# CTRL_MODULE_CORE register map
Vendor: Texas Instruments
Registers are 32-bit, read-only, reset 0x0 unless marked. A register's access mark holds for its fields unless they carry their own. Offsets are as the file gives them; [hi:lo] are bit positions; {n}, {i} and the like mark numbered series.

## CTRL_MODULE_CORE (part 2 of 2)
0x448 CONTROL_CONF_CLK_SEL2 access per field reset 0x2 — clk view channel 2 Access conditions. Read: unrestricted, Write: unrestricted
  [3:0] MULT rw — Select one of the following signals :
    6=MULT_I6 (hwobs_satadpll_clkout); 1=MULT_I1 (hwobs_abedpll_clkout); 10=MULT_I10 (Reserved); 7=MULT_I7 (hwobs_usbotgssdpll_clkout); 0=MULT_I0 (hwobs_coredpll_clkout); 2=MULT_I2 (hwobs_perdpll_clkout); 8=MULT_I8 (hwobs_usbdpll_clkout); 9=MULT_I9 (Reserved); 4=MULT_I4 (hwobs_dsi1cdpll_clkout); 5=MULT_I5 (hwobs_hdmidpll_clkout); 3=MULT_I3 (hwobs_dsi1adpll_clkout)
0x44C CONTROL_CONF_DPLL_FREQLOCK_SEL access per field — dpll_freqlock view Access conditions. Read: unrestricted, Write: unrestricted
  [3:0] MULT rw — Select one of the following signals :
    6=MULT_I6 (hwobs_satadpll_freqlock); 1=MULT_I1 (hwobs_abedpll_freqlock); 10=MULT_I10 (Reserved); 7=MULT_I7 (hwobs_usbotgssdpll_freqlock); 0=MULT_I0 (hwobs_coredpll_freqlock); 2=MULT_I2 (hwobs_perdpll_freqlock); 8=MULT_I8 (hwobs_usbdpll_freqlock); 9=MULT_I9 (Reserved); 4=MULT_I4 (hwobs_dsi1cdpll_freqlock); 5=MULT_I5 (hwobs_hdmidpll_freqlock); 3=MULT_I3 (hwobs_dsi1adpll_freqlock)
0x450 CONTROL_CONF_DPLL_TINITZ_SEL access per field — dpll_tinitz view Access conditions. Read: unrestricted, Write: unrestricted
  [3:0] MULT rw — Select one of the following signals :
    0=MULT_I0 (hwobs_coredpll_tinitz)
0x454 CONTROL_CONF_DPLL_PHASELOCK_SEL access per field — dpll_phaselock view Access conditions. Read: unrestricted, Write: unrestricted
  [3:0] MULT rw — Select one of the following signals :
    6=MULT_I6 (hwobs_satadpll_phaselock); 1=MULT_I1 (hwobs_abedpll_phaselock); 10=MULT_I10 (Reserved); 7=MULT_I7 (hwobs_usbotgssdpll_phaselock); 0=MULT_I0 (hwobs_coredpll_phaselock); 2=MULT_I2 (hwobs_perdpll_phaselock); 8=MULT_I8 (hwobs_usbdpll_phaselock); 9=MULT_I9 (Reserved); 4=MULT_I4 (hwobs_dsi1cdpll_phaselock); 5=MULT_I5 (hwobs_hdmidpll_phaselock); 3=MULT_I3 (hwobs_dsi1adpll_phaselock)
0x458 CONTROL_CONF_DPLL_TENABLE_SEL access per field — dpll_tenable view Access conditions. Read: unrestricted, Write: unrestricted
  [3:0] MULT rw — Select one of the following signals :
    6=MULT_I6 (hwobs_satadpll_tenable); 1=MULT_I1 (hwobs_abedpll_tenable); 10=MULT_I10 (Reserved); 7=MULT_I7 (hwobs_usbotgssdpll_tenable); 0=MULT_I0 (hwobs_coredpll_tenable); 2=MULT_I2 (hwobs_perdpll_tenable); 8=MULT_I8 (hwobs_usbdpll_tenable); 9=MULT_I9 (Reserved); 4=MULT_I4 (hwobs_dsi1cdpll_tenable); 5=MULT_I5 (hwobs_hdmidpll_tenable); 3=MULT_I3 (hwobs_dsi1adpll_tenable)
0x45C CONTROL_CONF_DPLL_TENABLEDIV_SEL access per field — dpll_tenablediv view Access conditions. Read: unrestricted, Write: unrestricted
  [3:0] MULT rw — Select one of the following signals :
    6=MULT_I6 (hwobs_satadpll_tenablediv); 1=MULT_I1 (hwobs_abedpll_tenablediv); 10=MULT_I10 (Reserved); 7=MULT_I7 (hwobs_usbotgssdpll_tenablediv); 0=MULT_I0 (hwobs_coredpll_tenablediv); 2=MULT_I2 (hwobs_perdpll_tenablediv); 8=MULT_I8 (hwobs_usbdpll_tenablediv); 9=MULT_I9 (Reserved); 4=MULT_I4 (hwobs_dsi1cdpll_tenablediv); 5=MULT_I5 (hwobs_hdmidpll_tenablediv); 3=MULT_I3 (hwobs_dsi1adpll_tenablediv)
0x460 CONTROL_CONF_DPLL_BYPASSACK_SEL access per field — dpll_bypassack view Access conditions. Read: unrestricted, Write: unrestricted
  [3:0] MULT rw — Select one of the following signals :
    6=MULT_I6 (hwobs_satadpll_bypassack); 1=MULT_I1 (hwobs_abedpll_bypassack); 10=MULT_I10 (Reserved); 7=MULT_I7 (hwobs_usbotgssdpll_bypassack); 0=MULT_I0 (hwobs_coredpll_bypassack); 2=MULT_I2 (hwobs_perdpll_bypassack); 8=MULT_I8 (hwobs_usbdpll_bypassack); 9=MULT_I9 (Reserved); 4=MULT_I4 (hwobs_dsi1cdpll_bypassack); 5=MULT_I5 (hwobs_hdmidpll_bypassack); 3=MULT_I3 (hwobs_dsi1adpll_bypassack)
0x464 CONTROL_CONF_DPLL_IDLE_SEL access per field — dpll_idle view Access conditions. Read: unrestricted, Write: unrestricted
  [3:0] MULT rw — Select one of the following signals :
    6=MULT_I6 (hwobs_satadpll_idle); 1=MULT_I1 (hwobs_abedpll_idle); 10=MULT_I10 (Reserved); 7=MULT_I7 (hwobs_usbotgssdpll_idle); 0=MULT_I0 (hwobs_coredpll_idle); 2=MULT_I2 (hwobs_perdpll_idle); 8=MULT_I8 (hwobs_usbdpll_idle); 9=MULT_I9 (Reserved); 4=MULT_I4 (hwobs_dsi1cdpll_idle); 5=MULT_I5 (hwobs_hdmidpll_idle); 3=MULT_I3 (hwobs_dsi1adpll_idle)
0x468 CONTROL_CONF_DPLLCTRL_PLLLOCK_SEL access per field — dpllctrl_plllock view Access conditions. Read: unrestricted, Write: unrestricted
  [2:0] MULT rw — Select one of the following signals :
    0=MULT_I0 (hwobs_dsi1a_plllock); 1=MULT_I1 (hwobs_dsi1c_plllock); 3=MULT_I3 (hwobs_sata_plllock); 4=MULT_I4 (hwobs_usbotgss_plllock); 2=MULT_I2 (hwobs_hdmi_plllock)
0x46C CONTROL_CONF_DPLLCTRL_PLLRECAL_SEL access per field — dpllctrl_pllrecal view Access conditions. Read: unrestricted, Write: unrestricted
  [2:0] MULT rw — Select one of the following signals :
    0=MULT_I0 (hwobs_dsi1a_pllrecal); 1=MULT_I1 (hwobs_dsi1c_pllrecal); 3=MULT_I3 (hwobs_sata_pllrecal); 4=MULT_I4 (hwobs_usbotgss_pllrecal); 2=MULT_I2 (hwobs_hdmi_pllrecal)
0x470 CONTROL_CONF_DPLLCTRL_STOPCLOCK_SEL access per field — dpllctrl_stopclock view Access conditions. Read: unrestricted, Write: unrestricted
  [2:0] MULT rw — Select one of the following signals :
    0=MULT_I0 (hwobs_dsi1a_stopclock); 1=MULT_I1 (hwobs_dsi1c_stopclock); 3=MULT_I3 (hwobs_sata_stopclock); 4=MULT_I4 (hwobs_usbotgss_stopclock); 2=MULT_I2 (hwobs_hdmi_stopclock)
0x474 CONTROL_CONF_DPLLCTRL_STOPCLOCKACKZ_SEL access per field — dpllctrl_stopclockackz view Access conditions. Read: unrestricted, Write: unrestricted
  [2:0] MULT rw — Select one of the following signals :
    0=MULT_I0 (hwobs_dsi1a_stopclockackz); 1=MULT_I1 (hwobs_dsi1c_stopclockackz); 3=MULT_I3 (hwobs_sata_stopclockackz); 4=MULT_I4 (hwobs_usbotgss_stopclockackz); 2=MULT_I2 (hwobs_hdmi_stopclockackz)
0x478 CONTROL_CONF_DPLLCTRL_DISPCUPDATESYNC_SEL access per field — dpllctrl_dispcupdatesync view Access conditions. Read: unrestricted, Write: unrestricted
  [2:0] MULT rw — Select one of the following signals :
    0=MULT_I0 (hwobs_dsi1a_dispcupdatesync); 1=MULT_I1 (hwobs_dsi1c_dispcupdatesync); 3=MULT_I3 (hwobs_sata_dispcupdatesync); 4=MULT_I4 (hwobs_usbotgss_dispcupdatesync); 2=MULT_I2 (hwobs_hdmi_dispcupdatesync)
0x4AC CONTROL_CONF_MMCX_ADPIDLE_SEL access per field — conf_mmcx_adpidle_view Access conditions. Read: unrestricted, Write: unrestricted
  [2:0] MULT rw — Select one of the following signals :
    {v}=MULT_I{v} (hwobs_mmc{v+1}_adpidle) (v=0..4)
0x4B0 CONTROL_CONF_MMCX_ADPDAT1PADEN_SEL access per field — conf_mmcx_adpdat1paden_view Access conditions. Read: unrestricted, Write: unrestricted
  [2:0] MULT rw — Select one of the following signals :
    {v}=MULT_I{v} (hwobs_mmc{v+1}_adpdat1paden) (v=0..4)
0x4B4 CONTROL_CONF_MMCX_OCPL4IDLEREQ_SEL access per field — conf_mmcx_ocpl4idlereq_view Access conditions. Read: unrestricted, Write: unrestricted
  [2:0] MULT rw — Select one of the following signals :
    {v}=MULT_I{v} (hwobs_mmc{v+1}_ocpl4idlereq) (v=0..4)
0x4B8 CONTROL_CONF_MMCX_OCPL3MWAIT_SEL access per field — conf_mmcx_ocpl3mwait_view Access conditions. Read: unrestricted, Write: unrestricted
  [2:0] MULT rw — Select one of the following signals :
    {v}=MULT_I{v} (hwobs_mmc{v+1}_ocpl3mwait) (v=0..4)
0x4BC CONTROL_CONF_MMCX_PIRFFRET_SEL access per field — conf_mmcx_pirffret_view Access conditions. Read: unrestricted, Write: unrestricted
  [2:0] MULT rw — Select one of the following signals :
    {v}=MULT_I{v} (hwobs_mmc{v+1}_pirffret) (v=0..4)
0x4C0 CONTROL_CONF_MMCX_OCPL4SIDLEACKO1_SEL access per field — conf_mmcx_ocpl4sidleacko1_view Access conditions. Read: unrestricted, Write: unrestricted
  [2:0] MULT rw — Select one of the following signals :
    {v}=MULT_I{v} (hwobs_mmc{v+1}_ocpl4sidleacko_1) (v=0..4)
0x4C4 CONTROL_CONF_MMCX_OCPL4SIDLEACKO0_SEL access per field — conf_mmcx_ocpl4sidleacko0_view Access conditions. Read: unrestricted, Write: unrestricted
  [2:0] MULT rw — Select one of the following signals :
    {v}=MULT_I{v} (hwobs_mmc{v+1}_ocpl4sidleacko_0) (v=0..4)
0x4C8 CONTROL_CONF_MMCX_OCPL3MSTANDBYO_SEL access per field — conf_mmcx_ocpl3mstandbyo_view Access conditions. Read: unrestricted, Write: unrestricted
  [2:0] MULT rw — Select one of the following signals :
    {v}=MULT_I{v} (hwobs_mmc{v+1}_ocpl3mstandbyo) (v=0..4)
0x4CC CONTROL_CONF_MMCX_SWAKEUP_SEL access per field — conf_mmcx_swakeup_view Access conditions. Read: unrestricted, Write: unrestricted
  [2:0] MULT rw — Select one of the following signals :
    {v}=MULT_I{v} (hwobs_mmc{v+1}_swakeup) (v=0..4)
0x4D0 CONTROL_CORE_CONF_DEBUG_SEL_TST_0 access per field — Select mode for debug port Access conditions. Read: unrestricted, Write: unrestricted
  [4:0] MODE rw — Select one of the following signals :
    {v}=MODE_I{v} (Reserved) (v=13..16); {v}=MODE_I{v} (Reserved) (v=18..28); 8=MODE_I8 (hwobs_debug_abe_0); 5=MODE_I5 (Reserved); 2=MODE_I2 (Reserved); 4=MODE_I4 (hwobs_debug_dsp_1); 6=MODE_I6 (hwobs_debug_ivahd_0); 1=MODE_I1 (clk_view_0); 29=MODE_I29 (hwobs_bb2d_sys_interrupt_reqz); 0=MODE_I0 (hwobs_debug_mpu_0); 11=MODE_I11 (Reserved); 3=MODE_I3 (Reserved); 17=MODE_I17 (dpllctrl_plllock); 10=MODE_I10 (Reserved); 9=MODE_I9 (hwobs_debug_dsp_0); 7=MODE_I7 (Reserved); 12=MODE_I12 (hwobs_debug_dsp_2)
0x4D4 CONTROL_CORE_CONF_DEBUG_SEL_TST_1 access per field — Select mode for debug port Access conditions. Read: unrestricted, Write: unrestricted
  [4:0] MODE rw — Select one of the following signals :
    {v}=MODE_I{v} (Reserved) (v=10..13); {v}=MODE_I{v} (Reserved) (v=18..28); 8=MODE_I8 (hwobs_debug_abe_1); {v}=MODE_I{v} (Reserved) (v=2..5); 6=MODE_I6 (hwobs_debug_ivahd_1); 1=MODE_I1 (clk_view_1); 0=MODE_I0 (hwobs_debug_mpu_1); 17=MODE_I17 (dpllctrl_pllrecal); 9=MODE_I9 (hwobs_debug_dsp_1); 16=MODE_I16 (Reserved); 14=MODE_I14 (hwobs_emif1_pwr_sidlereq); 7=MODE_I7 (Reserved); 15=MODE_I15 (Reserved)
0x4D8 CONTROL_CORE_CONF_DEBUG_SEL_TST_2 access per field — Select mode for debug port Access conditions. Read: unrestricted, Write: unrestricted
  [4:0] MODE rw — Select one of the following signals :
    13=MODE_I13 (Reserved); {v}=MODE_I{v} (Reserved) (v=18..28); 8=MODE_I8 (hwobs_debug_abe_2); {v}=MODE_I{v} (Reserved) (v=2..5); 6=MODE_I6 (hwobs_debug_ivahd_2); 1=MODE_I1 (clk_view_2); 0=MODE_I0 (hwobs_debug_mpu_2); 11=MODE_I11 (hwobs_dsshdmiphypwrcmdtxon); 17=MODE_I17 (dpllctrl_stopclock); 10=MODE_I10 (Reserved); 9=MODE_I9 (hwobs_debug_dsp_2); 16=MODE_I16 (Reserved); 14=MODE_I14 (hwobs_emif1_pwr_sidleack_1); 7=MODE_I7 (Reserved); 15=MODE_I15 (Reserved); 12=MODE_I12 (Reserved)
0x4DC CONTROL_CORE_CONF_DEBUG_SEL_TST_3 access per field — Select mode for debug port Access conditions. Read: unrestricted, Write: unrestricted
  [4:0] MODE rw — Select one of the following signals :
    13=MODE_I13 (Reserved); {v}=MODE_I{v} (Reserved) (v=18..28); 8=MODE_I8 (hwobs_debug_abe_3); {v}=MODE_I{v} (Reserved) (v=2..5); 6=MODE_I6 (hwobs_debug_ivahd_3); 1=MODE_I1 (dpll_freqlock); 0=MODE_I0 (hwobs_debug_mpu_3); 11=MODE_I11 (hwobs_dsshdmiphypwrcmdoff); 17=MODE_I17 (dpllctrl_stopclockackz); 10=MODE_I10 (Reserved); 9=MODE_I9 (hwobs_debug_dsp_3); 16=MODE_I16 (Reserved); 14=MODE_I14 (hwobs_emif1_pwr_sidleack_0); 7=MODE_I7 (Reserved); 15=MODE_I15 (Reserved); 12=MODE_I12 (Reserved)
0x4E0 CONTROL_CORE_CONF_DEBUG_SEL_TST_4 access per field — Select mode for debug port Access conditions. Read: unrestricted, Write: unrestricted
  [4:0] MODE rw — Select one of the following signals :
    13=MODE_I13 (Reserved); {v}=MODE_I{v} (Reserved) (v=18..28); 8=MODE_I8 (hwobs_debug_abe_4); {v}=MODE_I{v} (Reserved) (v=2..5); 6=MODE_I6 (hwobs_debug_ivahd_4); 1=MODE_I1 (dpll_tinitz); 0=MODE_I0 (hwobs_debug_mpu_4); 11=MODE_I11 (hwobs_dsshdmiphypwrack); 17=MODE_I17 (dpllctrl_dispcupdatesync); 10=MODE_I10 (Reserved); 9=MODE_I9 (hwobs_debug_dsp_4); 16=MODE_I16 (Reserved); 14=MODE_I14 (hwobs_emif1_pwr_fclken); 7=MODE_I7 (Reserved); 15=MODE_I15 (Reserved); 12=MODE_I12 (Reserved)
0x4E4 CONTROL_CORE_CONF_DEBUG_SEL_TST_5 access per field — Select mode for debug port Access conditions. Read: unrestricted, Write: unrestricted
  [4:0] MODE rw — Select one of the following signals :
    13=MODE_I13 (Reserved); {v}=MODE_I{v} (Reserved) (v=15..28); 8=MODE_I8 (hwobs_debug_abe_5); {v}=MODE_I{v} (Reserved) (v=2..5); 6=MODE_I6 (hwobs_debug_ivahd_5); 1=MODE_I1 (dpll_phaselock); 0=MODE_I0 (hwobs_debug_mpu_5); 11=MODE_I11 (hwobs_dsshdmihpd); 10=MODE_I10 (Reserved); 9=MODE_I9 (hwobs_debug_dsp_5); 14=MODE_I14 (hwobs_emif1_sys_err_intr_req); 7=MODE_I7 (Reserved); 12=MODE_I12 (Reserved)
0x4E8 CONTROL_CORE_CONF_DEBUG_SEL_TST_6 access per field — Select mode for debug port Access conditions. Read: unrestricted, Write: unrestricted
  [4:0] MODE rw — Select one of the following signals :
    {v}=MODE_I{v} (Reserved) (v=10..13); {v}=MODE_I{v} (Reserved) (v=15..28); 8=MODE_I8 (hwobs_debug_abe_6); {v}=MODE_I{v} (Reserved) (v=2..5); 6=MODE_I6 (hwobs_debug_ivahd_6); 1=MODE_I1 (dpll_tenable); 0=MODE_I0 (hwobs_debug_mpu_6); 9=MODE_I9 (hwobs_debug_dsp_6); 14=MODE_I14 (hwobs_emif1_sys_err_intr_pend); 7=MODE_I7 (Reserved)
0x4EC CONTROL_CORE_CONF_DEBUG_SEL_TST_7 access per field — Select mode for debug port Access conditions. Read: unrestricted, Write: unrestricted
  [4:0] MODE rw — Select one of the following signals :
    {v}=MODE_I{v} (Reserved) (v=10..13); {v}=MODE_I{v} (Reserved) (v=15..28); 8=MODE_I8 (hwobs_debug_abe_7); 5=MODE_I5 (Reserved); 2=MODE_I2 (sdma_req_view_0); 4=MODE_I4 (Reserved); 6=MODE_I6 (hwobs_debug_ivahd_7); 1=MODE_I1 (dpll_tenablediv); 0=MODE_I0 (hwobs_debug_mpu_7); 3=MODE_I3 (Reserved); 9=MODE_I9 (hwobs_debug_dsp_7); 14=MODE_I14 (hwobs_emif1_ll_err_intr_req); 7=MODE_I7 (Reserved)
0x4F0 CONTROL_CORE_CONF_DEBUG_SEL_TST_8 access per field — Select mode for debug port Access conditions. Read: unrestricted, Write: unrestricted
  [4:0] MODE rw — Select one of the following signals :
    {v}=MODE_I{v} (Reserved) (v=10..13); {v}=MODE_I{v} (Reserved) (v=15..28); 8=MODE_I8 (hwobs_debug_abe_8); 5=MODE_I5 (Reserved); 2=MODE_I2 (sdma_req_view_1); 4=MODE_I4 (Reserved); 6=MODE_I6 (hwobs_debug_ivahd_8); 1=MODE_I1 (dpll_bypassack); 0=MODE_I0 (hwobs_debug_mpu_8); 3=MODE_I3 (Reserved); 9=MODE_I9 (hwobs_debug_dsp_8); 14=MODE_I14 (hwobs_emif1_ll_err_intr_pend); 7=MODE_I7 (Reserved)
0x4F4 CONTROL_CORE_CONF_DEBUG_SEL_TST_9 access per field — Select mode for debug port Access conditions. Read: unrestricted, Write: unrestricted
  [4:0] MODE rw — Select one of the following signals :
    {v}=MODE_I{v} (Reserved) (v=10..13); {v}=MODE_I{v} (Reserved) (v=15..28); 8=MODE_I8 (hwobs_debug_abe_9); 5=MODE_I5 (Reserved); 2=MODE_I2 (sdma_req_view_2); 4=MODE_I4 (Reserved); 6=MODE_I6 (hwobs_debug_ivahd_9); 1=MODE_I1 (dpll_idle); 0=MODE_I0 (hwobs_debug_mpu_9); 3=MODE_I3 (Reserved); 9=MODE_I9 (hwobs_debug_dsp_9); 14=MODE_I14 (hwobs_emif1_ret_powerRet); 7=MODE_I7 (Reserved)
0x4F8 CONTROL_CORE_CONF_DEBUG_SEL_TST_10 access per field — Select mode for debug port Access conditions. Read: unrestricted, Write: unrestricted
  [4:0] MODE rw — Select one of the following signals :
    {v}=MODE_I{v} (Reserved) (v=10..28); 8=MODE_I8 (hwobs_debug_abe_10); 5=MODE_I5 (Reserved); 2=MODE_I2 (sdma_req_view_3); 4=MODE_I4 (Reserved); 6=MODE_I6 (hwobs_debug_ivahd_10); 1=MODE_I1 (Reserved); 29=MODE_I1 (Reserved); 0=MODE_I0 (hwobs_debug_mpu_10); 3=MODE_I3 (Reserved); 9=MODE_I9 (hwobs_debug_dsp_10); 7=MODE_I7 (Reserved)
0x4FC CONTROL_CORE_CONF_DEBUG_SEL_TST_11 access per field — Select mode for debug port Access conditions. Read: unrestricted, Write: unrestricted
  [4:0] MODE rw — Select one of the following signals :
    {v}=MODE_I{v} (Reserved) (v=10..28); 8=MODE_I8 (hwobs_debug_abe_11); 5=MODE_I5 (Reserved); 2=MODE_I2 (sdma_req_view_all); 4=MODE_I4 (Reserved); 6=MODE_I6 (hwobs_debug_ivahd_11); 1=MODE_I1 (hwobs_emif1_pwr_sidlereq); 0=MODE_I0 (hwobs_debug_mpu_11); 3=MODE_I3 (Reserved); 9=MODE_I9 (hwobs_debug_dsp_11); 7=MODE_I7 (Reserved)
0x500 CONTROL_CORE_CONF_DEBUG_SEL_TST_12 access per field — Select mode for debug port Access conditions. Read: unrestricted, Write: unrestricted
  [4:0] MODE rw — Select one of the following signals :
    {v}=MODE_I{v} (Reserved) (v=10..28); 8=MODE_I8 (hwobs_debug_abe_12); 5=MODE_I5 (Reserved); 2=MODE_I2 (hwobs_coredivider_clkout3); 4=MODE_I4 (Reserved); 6=MODE_I6 (hwobs_debug_ivahd_12); 1=MODE_I1 (hwobs_emif1_pwr_sidleack_1); 0=MODE_I0 (hwobs_debug_mpu_12); 3=MODE_I3 (Reserved); 9=MODE_I9 (hwobs_debug_dsp_12); 7=MODE_I7 (Reserved)
0x504 CONTROL_CORE_CONF_DEBUG_SEL_TST_13 access per field — Select mode for debug port Access conditions. Read: unrestricted, Write: unrestricted
  [4:0] MODE rw — Select one of the following signals :
    {v}=MODE_I{v} (Reserved) (v=10..13); {v}=MODE_I{v} (Reserved) (v=15..28); 8=MODE_I8 (hwobs_debug_abe_13); 5=MODE_I5 (Reserved); 2=MODE_I2 (hwobs_perdivider_clkout4); 4=MODE_I4 (Reserved); 6=MODE_I6 (hwobs_debug_ivahd_13); 1=MODE_I1 (hwobs_emif1_pwr_sidleack_0); 0=MODE_I0 (hwobs_debug_mpu_13); 3=MODE_I3 (Reserved); 9=MODE_I9 (hwobs_debug_dsp_13); 14=MODE_I14 (hwobs_emif2_pwr_sidlereq); 7=MODE_I7 (Reserved)
0x508 CONTROL_CORE_CONF_DEBUG_SEL_TST_14 access per field — Select mode for debug port Access conditions. Read: unrestricted, Write: unrestricted
  [4:0] MODE rw — Select one of the following signals :
    {v}=MODE_I{v} (Reserved) (v=10..28); 8=MODE_I8 (hwobs_debug_abe_14); 5=MODE_I5 (Reserved); 2=MODE_I2 (hwobs_pd_l4_per_per32k_gfclk); 4=MODE_I4 (Reserved); 6=MODE_I6 (hwobs_debug_ivahd_14); 1=MODE_I1 (hwobs_emif1_pwr_fclken); 0=MODE_I0 (hwobs_debug_mpu_14); 3=MODE_I3 (Reserved); 9=MODE_I9 (hwobs_debug_dsp_14); 7=MODE_I7 (Reserved)
0x50C CONTROL_CORE_CONF_DEBUG_SEL_TST_15 access per field — Select mode for debug port Access conditions. Read: unrestricted, Write: unrestricted
  [4:0] MODE rw — Select one of the following signals :
    {v}=MODE_I{v} (Reserved) (v=10..13); {v}=MODE_I{v} (Reserved) (v=18..28); 8=MODE_I8 (hwobs_debug_abe_15); 5=MODE_I5 (Reserved); 2=MODE_I2 ('0'); 4=MODE_I4 (Reserved); 6=MODE_I6 (hwobs_debug_ivahd_15); 1=MODE_I1 (hwobs_emif1_sys_err_intr_req); 0=MODE_I0 (hwobs_debug_mpu_15); 3=MODE_I3 (Reserved); 17=MODE_I17 (dpll_freqlock); 9=MODE_I9 (hwobs_debug_dsp_15); 16=MODE_I16 (Reserved); 14=MODE_I14 (hwobs_emif2_pwr_sidleack_0); 7=MODE_I7 (Reserved); 15=MODE_I15 (Reserved)
0x510 CONTROL_CORE_CONF_DEBUG_SEL_TST_16 access per field — Select mode for debug port Access conditions. Read: unrestricted, Write: unrestricted
  [4:0] MODE rw — Select one of the following signals :
    {v}=MODE_I{v} (Reserved) (v=10..13); {v}=MODE_I{v} (Reserved) (v=18..28); 8=MODE_I8 (hwobs_debug_abe_16); 5=MODE_I5 (Reserved); 2=MODE_I2 (geni); 4=MODE_I4 (Reserved); 6=MODE_I6 (hwobs_debug_ivahd_16); 1=MODE_I1 (hwobs_emif1_sys_err_intr_pend); 0=MODE_I0 (hwobs_debug_mpu_16); 3=MODE_I3 (Reserved); 17=MODE_I17 (dpll_tinitz); 9=MODE_I9 (hwobs_debug_dsp_16); 16=MODE_I16 (Reserved); 14=MODE_I14 (hwobs_emif2_pwr_fclken); 7=MODE_I7 (Reserved); 15=MODE_I15 (Reserved)
0x514 CONTROL_CORE_CONF_DEBUG_SEL_TST_17 access per field — Select mode for debug port Access conditions. Read: unrestricted, Write: unrestricted
  [4:0] MODE rw — Select one of the following signals :
    {v}=MODE_I{v} (Reserved) (v=10..13); {v}=MODE_I{v} (Reserved) (v=18..28); 8=MODE_I8 (hwobs_debug_abe_17); 5=MODE_I5 (Reserved); 2=MODE_I2 (geno); 4=MODE_I4 (Reserved); 6=MODE_I6 (hwobs_debug_ivahd_17); 1=MODE_I1 (hwobs_emif1_ll_err_intr_req); 0=MODE_I0 (hwobs_debug_mpu_17); 3=MODE_I3 (Reserved); 17=MODE_I17 (dpll_phaselock); 9=MODE_I9 (hwobs_debug_dsp_17); 16=MODE_I16 (Reserved); 14=MODE_I14 (hwobs_emif2_sys_err_intr_req); 7=MODE_I7 (Reserved); 15=MODE_I15 (Reserved)
0x518 CONTROL_CORE_CONF_DEBUG_SEL_TST_18 access per field — Select mode for debug port Access conditions. Read: unrestricted, Write: unrestricted
  [4:0] MODE rw — Select one of the following signals :
    {v}=MODE_I{v} (Reserved) (v=10..13); {v}=MODE_I{v} (Reserved) (v=18..28); 8=MODE_I8 (hwobs_debug_abe_18); {v}=MODE_I{v} (Reserved) (v=2..5); 6=MODE_I6 (hwobs_debug_ivahd_18); 1=MODE_I1 (hwobs_emif1_ll_err_intr_pend); 0=MODE_I0 (hwobs_debug_mpu_18); 17=MODE_I17 (dpll_tenable); 9=MODE_I9 (hwobs_debug_dsp_18); 16=MODE_I16 (Reserved); 14=MODE_I14 (hwobs_emif2_sys_err_intr_pend); 7=MODE_I7 (Reserved); 15=MODE_I15 (Reserved)
0x51C CONTROL_CORE_CONF_DEBUG_SEL_TST_19 access per field — Select mode for debug port Access conditions. Read: unrestricted, Write: unrestricted
  [4:0] MODE rw — Select one of the following signals :
    {v}=MODE_I{v} (Reserved) (v=10..13); {v}=MODE_I{v} (Reserved) (v=18..28); 8=MODE_I8 (hwobs_debug_abe_19); {v}=MODE_I{v} (Reserved) (v=2..5); 6=MODE_I6 (hwobs_debug_ivahd_19); 1=MODE_I1 (hwobs_emif1_ret_powerRet); 0=MODE_I0 (hwobs_debug_mpu_19); 17=MODE_I17 (dpll_tenablediv); 9=MODE_I9 (hwobs_debug_dsp_19); 16=MODE_I16 (Reserved); 14=MODE_I14 (hwobs_emif2_ll_err_intr_req); 7=MODE_I7 (Reserved); 15=MODE_I15 (Reserved)
0x520 CONTROL_CORE_CONF_DEBUG_SEL_TST_20 access per field — Select mode for debug port Access conditions. Read: unrestricted, Write: unrestricted
  [4:0] MODE rw — Select one of the following signals :
    {v}=MODE_I{v} (Reserved) (v=10..13); {v}=MODE_I{v} (Reserved) (v=18..28); 8=MODE_I8 (hwobs_debug_abe_20); {v}=MODE_I{v} (Reserved) (v=1..5); 6=MODE_I6 (hwobs_debug_ivahd_20); 0=MODE_I0 (hwobs_debug_mpu_20); 17=MODE_I17 (dpll_bypassack); 9=MODE_I9 (hwobs_debug_dsp_20); 16=MODE_I16 (Reserved); 14=MODE_I14 (hwobs_emif2_ll_err_intr_pend); 7=MODE_I7 (Reserved); 15=MODE_I15 (Reserved)
0x524 CONTROL_CORE_CONF_DEBUG_SEL_TST_21 access per field — Select mode for debug port Access conditions. Read: unrestricted, Write: unrestricted
  [4:0] MODE rw — Select one of the following signals :
    13=MODE_I13 (hwobs_hsi_sidlereq); {v}=MODE_I{v} (Reserved) (v=18..28); 8=MODE_I8 (hwobs_debug_abe_21); {v}=MODE_I{v} (Reserved) (v=1..5); 6=MODE_I6 (hwobs_debug_ivahd_21); 0=MODE_I0 (hwobs_debug_mpu_21); 11=MODE_I11 (Reserved); 17=MODE_I17 (dpll_idle); 10=MODE_I10 (Reserved); 9=MODE_I9 (hwobs_debug_dsp_21); 16=MODE_I16 (Reserved); 14=MODE_I14 (hwobs_emif2_ret_powerret); 7=MODE_I7 (Reserved); 15=MODE_I15 (Reserved); 12=MODE_I12 (Reserved)
0x528 CONTROL_CORE_CONF_DEBUG_SEL_TST_22 access per field — Select mode for debug port Access conditions. Read: unrestricted, Write: unrestricted
  [4:0] MODE rw — Select one of the following signals :
    13=MODE_I13 (hwobs_hsi_fclken); {v}=MODE_I{v} (Reserved) (v=18..27); 8=MODE_I8 (hwobs_debug_abe_22); {v}=MODE_I{v} (Reserved) (v=2..5); 6=MODE_I6 (hwobs_debug_ivahd_22); 1=MODE_I1 (hwobs_emif2_pwr_sidlereq); 0=MODE_I0 (hwobs_debug_mpu_22); 11=MODE_I11 (Reserved); 17=MODE_I17 (mmcx_adpidle); 10=MODE_I10 (Reserved); 9=MODE_I9 (hwobs_debug_dsp_22); 16=MODE_I16 (Reserved); 14=MODE_I14 (Reserved); 7=MODE_I7 (Reserved); 15=MODE_I15 (Reserved); 12=MODE_I12 (Reserved)
0x52C CONTROL_CORE_CONF_DEBUG_SEL_TST_23 access per field — Select mode for debug port Access conditions. Read: unrestricted, Write: unrestricted
  [4:0] MODE rw — Select one of the following signals :
    13=MODE_I13 (hwobs_hsi_swakeup_1); {v}=MODE_I{v} (Reserved) (v=18..27); 8=MODE_I8 (hwobs_debug_abe_23); {v}=MODE_I{v} (Reserved) (v=2..5); 6=MODE_I6 (hwobs_debug_ivahd_23); 1=MODE_I1 (hwobs_emif2_pwr_sidleack_1); 0=MODE_I0 (hwobs_debug_mpu_23); 11=MODE_I11 (Reserved); 17=MODE_I17 (mmcx_adpdat1paden); 10=MODE_I10 (Reserved); 9=MODE_I9 (hwobs_debug_dsp_23); 16=MODE_I16 (Reserved); 14=MODE_I14 (Reserved); 7=MODE_I7 (Reserved); 15=MODE_I15 (Reserved); 12=MODE_I12 (Reserved)
0x530 CONTROL_CORE_CONF_DEBUG_SEL_TST_24 access per field — Select mode for debug port Access conditions. Read: unrestricted, Write: unrestricted
  [4:0] MODE rw — Select one of the following signals :
    13=MODE_I13 (hwobs_hsi_swakeup_0); {v}=MODE_I{v} (Reserved) (v=18..27); 8=MODE_I8 (hwobs_debug_abe_24); {v}=MODE_I{v} (Reserved) (v=2..5); 6=MODE_I6 (hwobs_debug_ivahd_24); 1=MODE_I1 (hwobs_emif2_pwr_sidleack_0); 0=MODE_I0 (hwobs_debug_mpu_24); 11=MODE_I11 (Reserved); 17=MODE_I17 (mmcx_ocpl4idlereq); 10=MODE_I10 (Reserved); 9=MODE_I9 (hwobs_debug_dsp_24); 16=MODE_I16 (Reserved); 14=MODE_I14 ('0'); 7=MODE_I7 (Reserved); 15=MODE_I15 (Reserved); 12=MODE_I12 (Reserved)
0x534 CONTROL_CORE_CONF_DEBUG_SEL_TST_25 access per field — Select mode for debug port Access conditions. Read: unrestricted, Write: unrestricted
  [4:0] MODE rw — Select one of the following signals :
    13=MODE_I13 (hwobs_hsi_sidleack_1); {v}=MODE_I{v} (Reserved) (v=18..27); 8=MODE_I8 (hwobs_debug_abe_25); {v}=MODE_I{v} (Reserved) (v=2..5); 6=MODE_I6 (hwobs_debug_ivahd_25); 1=MODE_I1 (hwobs_emif2_pwr_fclken); 0=MODE_I0 (hwobs_debug_mpu_25); 11=MODE_I11 (Reserved); 17=MODE_I17 (mmcx_ocpl3mwait); 10=MODE_I10 (Reserved); 9=MODE_I9 (hwobs_debug_dsp_25); 16=MODE_I16 (Reserved); 14=MODE_I14 ('0'); 7=MODE_I7 (Reserved); 15=MODE_I15 (Reserved); 12=MODE_I12 ('0')
0x538 CONTROL_CORE_CONF_DEBUG_SEL_TST_26 access per field — Select mode for debug port Access conditions. Read: unrestricted, Write: unrestricted
  [4:0] MODE rw — Select one of the following signals :
    13=MODE_I13 (hwobs_hsi_sidleack_0); {v}=MODE_I{v} (Reserved) (v=18..27); 8=MODE_I8 (hwobs_debug_abe_26); 5=MODE_I5 (Reserved); 2=MODE_I2 (Reserved); 4=MODE_I4 (hwobs_dmm_ocpclken); 6=MODE_I6 (hwobs_debug_ivahd_26); 1=MODE_I1 (hwobs_emif2_sys_err_intr_req); 0=MODE_I0 (hwobs_debug_mpu_26); 11=MODE_I11 ('0'); 3=MODE_I3 (Reserved); 17=MODE_I17 (mmcx_pirffret); 10=MODE_I10 (Reserved); 9=MODE_I9 (hwobs_debug_dsp_26); 16=MODE_I16 (Reserved); 14=MODE_I14 ('0'); 7=MODE_I7 (Reserved); 15=MODE_I15 (Reserved); 12=MODE_I12 ('0')
0x53C CONTROL_CORE_CONF_DEBUG_SEL_TST_27 access per field — Select mode for debug port Access conditions. Read: unrestricted, Write: unrestricted
  [4:0] MODE rw — Select one of the following signals :
    13=MODE_I13 (hwobs_hsi_mwakeup); {v}=MODE_I{v} (Reserved) (v=18..27); 8=MODE_I8 (hwobs_debug_abe_27); 5=MODE_I5 (Reserved); 2=MODE_I2 (Reserved); 4=MODE_I4 (hwobs_dmm_rstna); 6=MODE_I6 (hwobs_debug_ivahd_27); 1=MODE_I1 (hwobs_emif2_sys_err_intr_pend); 0=MODE_I0 (hwobs_debug_mpu_27); 11=MODE_I11 ('0'); 3=MODE_I3 (Reserved); 17=MODE_I17 (mmcx_ocpl4sidleacko1); 10=MODE_I10 (Reserved); 9=MODE_I9 (hwobs_debug_dsp_27); 16=MODE_I16 (Reserved); 14=MODE_I14 ('0'); 7=MODE_I7 (Reserved); 15=MODE_I15 (Reserved); 12=MODE_I12 (sdma_req_view_0)
0x540 CONTROL_CORE_CONF_DEBUG_SEL_TST_28 access per field — Select mode for debug port Access conditions. Read: unrestricted, Write: unrestricted
  [4:0] MODE rw — Select one of the following signals :
    13=MODE_I13 (hwobs_hsi_mwait); {v}=MODE_I{v} (Reserved) (v=18..27); 8=MODE_I8 (hwobs_debug_abe_28); 5=MODE_I5 (Reserved); 2=MODE_I2 (Reserved); 4=MODE_I4 (hwobs_dmm_rstretna); 6=MODE_I6 (hwobs_debug_ivahd_28); 1=MODE_I1 (hwobs_emif2_ll_err_intr_req); 0=MODE_I0 (hwobs_debug_mpu_28); 11=MODE_I11 ('0'); 3=MODE_I3 (Reserved); 17=MODE_I17 (mmcx_ocpl4sidleacko0); 10=MODE_I10 (Reserved); 9=MODE_I9 (hwobs_debug_dsp_28); 16=MODE_I16 (Reserved); 14=MODE_I14 ('0'); 7=MODE_I7 (Reserved); 15=MODE_I15 (Reserved); 12=MODE_I12 (sdma_req_view_1)
0x544 CONTROL_CORE_CONF_DEBUG_SEL_TST_29 access per field — Select mode for debug port Access conditions. Read: unrestricted, Write: unrestricted
  [4:0] MODE rw — Select one of the following signals :
    13=MODE_I13 (hwobs_hsi_mstandby); {v}=MODE_I{v} (Reserved) (v=18..27); 8=MODE_I8 (hwobs_debug_abe_29); 5=MODE_I5 (Reserved); 2=MODE_I2 ('0'); 4=MODE_I4 (hwobs_dmm_idlereq); 6=MODE_I6 (hwobs_debug_ivahd_29); 1=MODE_I1 (hwobs_emif2_ll_err_intr_pend); 0=MODE_I0 (hwobs_debug_mpu_29); 11=MODE_I11 ('0'); 3=MODE_I3 (Reserved); 17=MODE_I17 (mmcx_ocpl3mstandbyo); 10=MODE_I10 (Reserved); 9=MODE_I9 (hwobs_debug_dsp_29); 16=MODE_I16 (Reserved); 14=MODE_I14 ('0'); 7=MODE_I7 (Reserved); 15=MODE_I15 (Reserved); 12=MODE_I12 (sdma_req_view_2)
0x548 CONTROL_CORE_CONF_DEBUG_SEL_TST_30 access per field — Select mode for debug port Access conditions. Read: unrestricted, Write: unrestricted
  [4:0] MODE rw — Select one of the following signals :
    13=MODE_I13 (hwobs_hsi_retff); {v}=MODE_I{v} (Reserved) (v=18..27); 8=MODE_I8 (hwobs_debug_abe_30); 5=MODE_I5 (Reserved); 2=MODE_I2 (Reserved); 4=MODE_I4 (hwobs_dmm_idleack_1); 6=MODE_I6 (hwobs_debug_ivahd_30); 1=MODE_I1 (hwobs_emif2_ret_powerret); 0=MODE_I0 (hwobs_debug_mpu_30); 11=MODE_I11 ('0'); 3=MODE_I3 (Reserved); 17=MODE_I17 (mmcx_swakeup); 10=MODE_I10 (Reserved); 9=MODE_I9 (hwobs_debug_dsp_30); 16=MODE_I16 (Reserved); 14=MODE_I14 ('0'); 7=MODE_I7 (Reserved); 15=MODE_I15 (Reserved); 12=MODE_I12 (sdma_req_view_3)
0x54C CONTROL_CORE_CONF_DEBUG_SEL_TST_31 access per field — Select mode for debug port Access conditions. Read: unrestricted, Write: unrestricted
  [4:0] MODE rw — Select one of the following signals :
    6=MODE_I6 (hwobs_debug_ivahd_31); 1=MODE_I1 (Reserved); 10=MODE_I10 (Reserved); 17=MODE_I17 ('0'); 7=MODE_I7 (Reserved); 13=MODE_I13 ('0'); 0=MODE_I0 (hwobs_debug_mpu_31); 2=MODE_I2 (Reserved); 8=MODE_I8 (hwobs_debug_abe_31); 9=MODE_I9 (hwobs_debug_dsp_31); 16=MODE_I16 (Reserved); 18=MODE_I18 (Reserved); 11=MODE_I11 ('0'); 19=MODE_I19 (Reserved); 4=MODE_I4 (hwobs_dmm_idleack_0); 5=MODE_I5 (Reserved); 15=MODE_I15 (Reserved); 12=MODE_I12 (sdma_req_view_all); 3=MODE_I3 (Reserved); 20=MODE_I20 (Reserved); 14=MODE_I14 (Reserved)
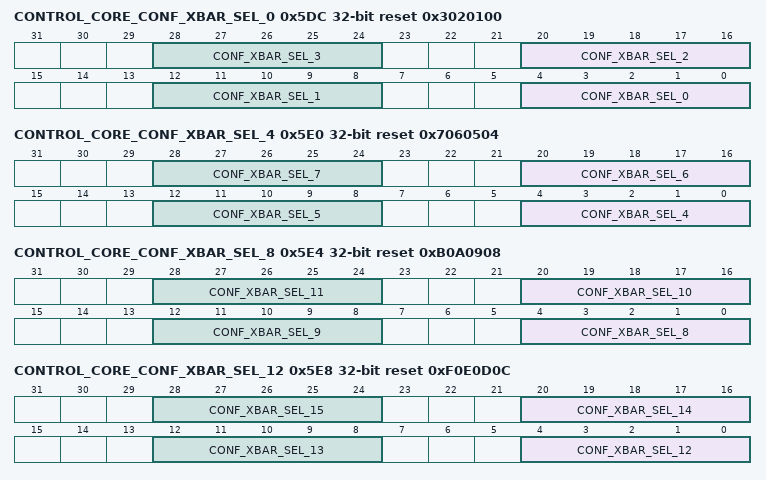
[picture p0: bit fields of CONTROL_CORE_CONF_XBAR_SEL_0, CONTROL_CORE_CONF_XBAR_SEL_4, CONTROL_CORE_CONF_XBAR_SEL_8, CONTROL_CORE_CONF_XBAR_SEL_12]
0x5DC CONTROL_CORE_CONF_XBAR_SEL_0 access per field reset 0x3020100 — Access conditions. Read: unrestricted, Write: unrestricted
  [8n+4:8n] CONF_XBAR_SEL_{n} rw (n=0..3) — Select for xbar test_port_{n}
0x5E0 CONTROL_CORE_CONF_XBAR_SEL_4 access per field reset 0x7060504 — Access conditions. Read: unrestricted, Write: unrestricted
  [8n-28:8n-32] CONF_XBAR_SEL_{n} rw (n=4..7) — Select for xbar test_port_{n}
0x5E4 CONTROL_CORE_CONF_XBAR_SEL_8 access per field reset 0xB0A0908 — Access conditions. Read: unrestricted, Write: unrestricted
  [8n-60:8n-64] CONF_XBAR_SEL_{n} rw (n=8..11) — Select for xbar test_port_{n}
0x5E8 CONTROL_CORE_CONF_XBAR_SEL_12 access per field reset 0xF0E0D0C — Access conditions. Read: unrestricted, Write: unrestricted
  [8n-92:8n-96] CONF_XBAR_SEL_{n} rw (n=12..15) — Select for xbar test_port_{n}
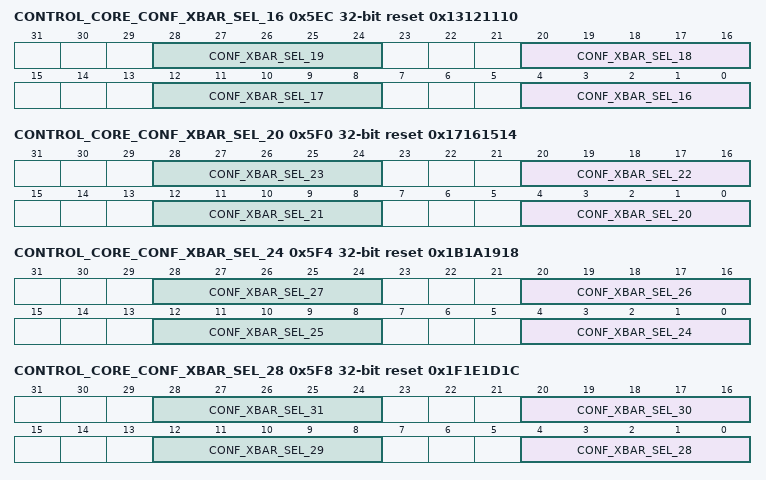
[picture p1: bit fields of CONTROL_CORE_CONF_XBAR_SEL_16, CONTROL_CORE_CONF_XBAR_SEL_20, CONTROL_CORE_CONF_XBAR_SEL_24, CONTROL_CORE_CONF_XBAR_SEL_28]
0x5EC CONTROL_CORE_CONF_XBAR_SEL_16 access per field reset 0x13121110 — Access conditions. Read: unrestricted, Write: unrestricted
  [8n-124:8n-128] CONF_XBAR_SEL_{n} rw (n=16..19) — Select for xbar test_port_{n}
0x5F0 CONTROL_CORE_CONF_XBAR_SEL_20 access per field reset 0x17161514 — Access conditions. Read: unrestricted, Write: unrestricted
  [8n-156:8n-160] CONF_XBAR_SEL_{n} rw (n=20..23) — Select for xbar test_port_{n}
0x5F4 CONTROL_CORE_CONF_XBAR_SEL_24 access per field reset 0x1B1A1918 — Access conditions. Read: unrestricted, Write: unrestricted
  [8n-188:8n-192] CONF_XBAR_SEL_{n} rw (n=24..27) — Select for xbar test_port_{n}
0x5F8 CONTROL_CORE_CONF_XBAR_SEL_28 access per field reset 0x1F1E1D1C — Access conditions. Read: unrestricted, Write: unrestricted
  [8n-220:8n-224] CONF_XBAR_SEL_{n} rw (n=28..31) — Select for xbar test_port_{n}
0x5FC CONTROL_CORE_CONF_XBAR_BYPASS access per field reset 0x1 — Crossbar bypass control register Access conditions. Read: unrestricted, Write: unrestricted
  [0] SELECT rw — Crossbar enable/disable
    0=enable_crossbar (Crossbar is enabled); 1=disable_crossbar (Crossbar is disabled (baypassed))
